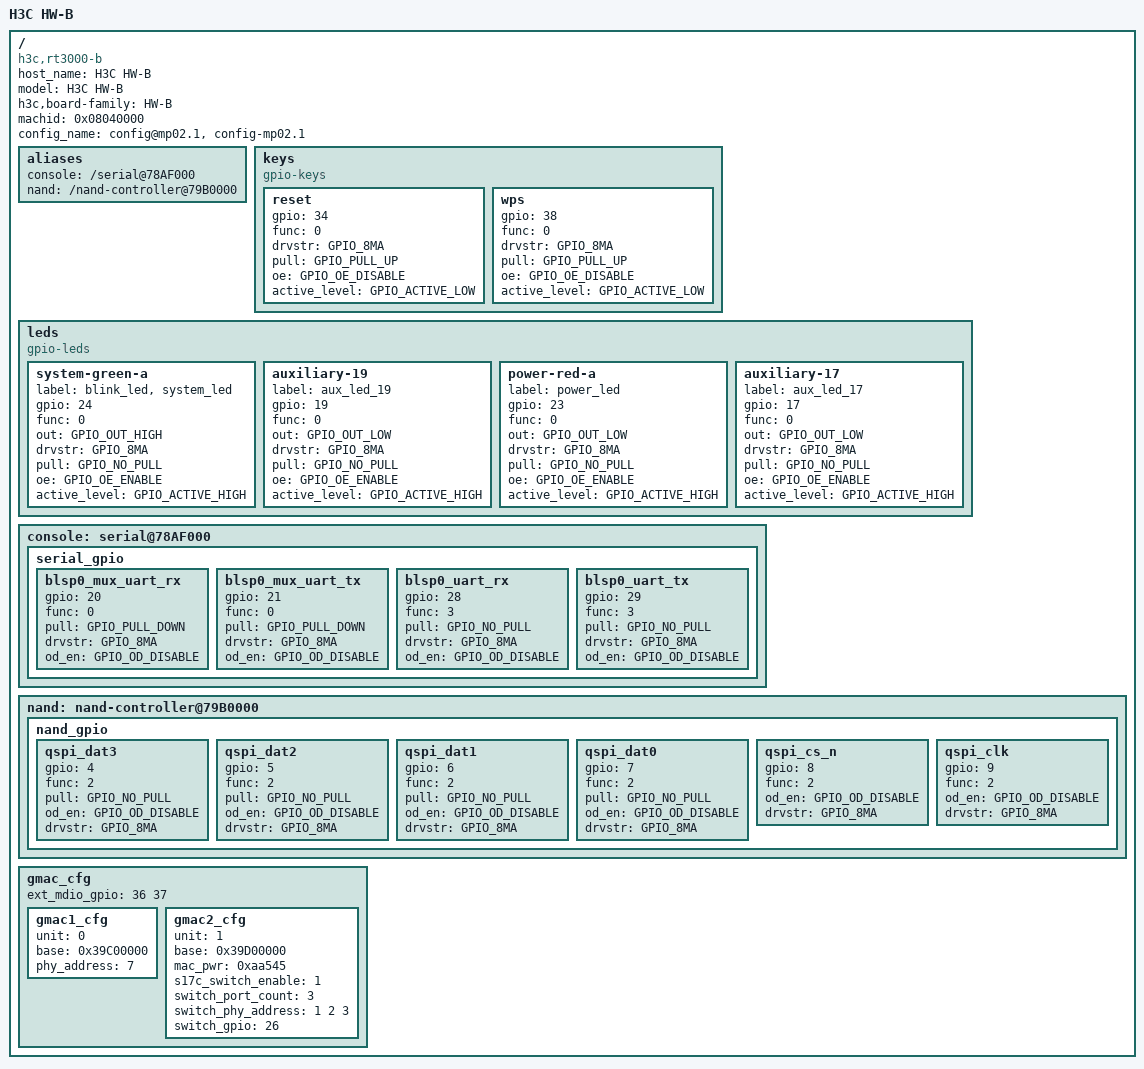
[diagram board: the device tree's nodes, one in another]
/*
 * Copyright (c) 2016-2020, The Linux Foundation. All rights reserved.
 *
 * This program is free software; you can redistribute it and/or modify
 * it under the terms of the GNU General Public License version 2 and
 * only version 2 as published by the Free Software Foundation.
 *
 * This program is distributed in the hope that it will be useful,
 * but WITHOUT ANY WARRANTY; without even the implied warranty of
 * MERCHANTABILITY or FITNESS FOR A PARTICULAR PURPOSE.  See the
 * GNU General Public License for more details.
 */

/dts-v1/;
#include "ipq5018-soc.dtsi"
/ {
	host_name = "H3C HW-B";
	model = "H3C HW-B";
	h3c,board-family = "HW-B";
	compatible = "h3c,rt3000-b", "qca,ipq5018";
	/* Verified on RT3000-B OEM U-Boot: bdinfo arch_number = 0x08040000. */
	machid = <0x08040000>;
	config_name = "config@mp02.1", "config-mp02.1";

	aliases {
		console = "/serial@78AF000";
		nand = "/nand-controller@79B0000";
	};

    keys {
		compatible = "gpio-keys";
		/* OEM input pinctrl; live press test: RESET=GPIO34 and WPS/MESH=GPIO38, both active-low. */

        reset {
            gpio = <34>;
            func = <0>;
            drvstr = <GPIO_8MA>;
            pull = <GPIO_PULL_UP>;
            oe = <GPIO_OE_DISABLE>;
			active_level = <GPIO_ACTIVE_LOW>;
        };

        wps {
            gpio = <38>;
            func = <0>;
            drvstr = <GPIO_8MA>;
            pull = <GPIO_PULL_UP>;
            oe = <GPIO_OE_DISABLE>;
			active_level = <GPIO_ACTIVE_LOW>;
        };
    };

	/*
	 * RT-B01 single-output visual check: green GPIO24, red GPIO23, active-high.
	 * GPIO19/17 are retained auxiliary outputs, held off during U-Boot.
	 * Green at startup/rescue; red for RESET countdown and failure.
	 */
	leds {
		compatible = "gpio-leds";

		system-green-a {
			label = "blink_led", "system_led";
			gpio = <24>;
			func = <0>;
			out = <GPIO_OUT_HIGH>;
			drvstr = <GPIO_8MA>;
			pull = <GPIO_NO_PULL>;
			oe = <GPIO_OE_ENABLE>;
			active_level = <GPIO_ACTIVE_HIGH>;
		};

		auxiliary-19 {
			label = "aux_led_19";
			gpio = <19>;
			func = <0>;
			out = <GPIO_OUT_LOW>;
			drvstr = <GPIO_8MA>;
			pull = <GPIO_NO_PULL>;
			oe = <GPIO_OE_ENABLE>;
			active_level = <GPIO_ACTIVE_HIGH>;
		};

		power-red-a {
			label = "power_led";
			gpio = <23>;
			func = <0>;
			out = <GPIO_OUT_LOW>;
			drvstr = <GPIO_8MA>;
			pull = <GPIO_NO_PULL>;
			oe = <GPIO_OE_ENABLE>;
			active_level = <GPIO_ACTIVE_HIGH>;
		};

		auxiliary-17 {
			label = "aux_led_17";
			gpio = <17>;
			func = <0>;
			out = <GPIO_OUT_LOW>;
			drvstr = <GPIO_8MA>;
			pull = <GPIO_NO_PULL>;
			oe = <GPIO_OE_ENABLE>;
			active_level = <GPIO_ACTIVE_HIGH>;
		};
	};

	console: serial@78AF000 {
		status = "ok";
		serial_gpio {
			/* Match OEM mp02.1 UART mux preparation before selecting RX28/TX29. */
			blsp0_mux_uart_rx {
				gpio = <20>;
				func = <0>;
				pull = <GPIO_PULL_DOWN>;
				drvstr = <GPIO_8MA>;
				od_en = <GPIO_OD_DISABLE>;
			};
			blsp0_mux_uart_tx {
				gpio = <21>;
				func = <0>;
				pull = <GPIO_PULL_DOWN>;
				drvstr = <GPIO_8MA>;
				od_en = <GPIO_OD_DISABLE>;
			};
			blsp0_uart_rx {
				gpio = <28>;
				func = <3>;
				pull = <GPIO_NO_PULL>;
				drvstr = <GPIO_8MA>;
				od_en = <GPIO_OD_DISABLE>;
			};
			blsp0_uart_tx {
				gpio = <29>;
				func = <3>;
				pull = <GPIO_NO_PULL>;
				drvstr = <GPIO_8MA>;
				od_en = <GPIO_OD_DISABLE>;
			};
		};
	};

	nand: nand-controller@79B0000 {
		status = "okay";
		nand_gpio {
			qspi_dat3 {
				gpio = <4>;
				func = <2>;
				pull = <GPIO_NO_PULL>;
				od_en = <GPIO_OD_DISABLE>;
				drvstr = <GPIO_8MA>;
			};
			qspi_dat2 {
				gpio = <5>;
				func = <2>;
				pull = <GPIO_NO_PULL>;
				od_en = <GPIO_OD_DISABLE>;
				drvstr = <GPIO_8MA>;
			};
			qspi_dat1 {
				gpio = <6>;
				func = <2>;
				pull = <GPIO_NO_PULL>;
				od_en = <GPIO_OD_DISABLE>;
				drvstr = <GPIO_8MA>;
			};
			qspi_dat0 {
				gpio = <7>;
				func = <2>;
				pull = <GPIO_NO_PULL>;
				od_en = <GPIO_OD_DISABLE>;
				drvstr = <GPIO_8MA>;
			};
			qspi_cs_n {
				gpio = <8>;
				func = <2>;
				od_en = <GPIO_OD_DISABLE>;
				drvstr = <GPIO_8MA>;
			};
			qspi_clk {
				gpio = <9>;
				func = <2>;
				od_en = <GPIO_OD_DISABLE>;
				drvstr = <GPIO_8MA>;
			};
		};
	};

	gmac_cfg {
		ext_mdio_gpio = <36 37>;

		gmac1_cfg {
			unit = <0>;
			base = <0x39C00000>;
			phy_address = <7>;
		};
		gmac2_cfg {
			unit = <1>;
			base = <0x39D00000>;
			mac_pwr = <0xaa545>;
			s17c_switch_enable = <1>;
			/* OEM MDIO reg 0x11: links on PHY1/2/3; PHY0/4 disconnected. */
			switch_port_count = <3>;
			switch_phy_address = <1 2 3>;
			switch_gpio = <26>;
		};
	};
};
